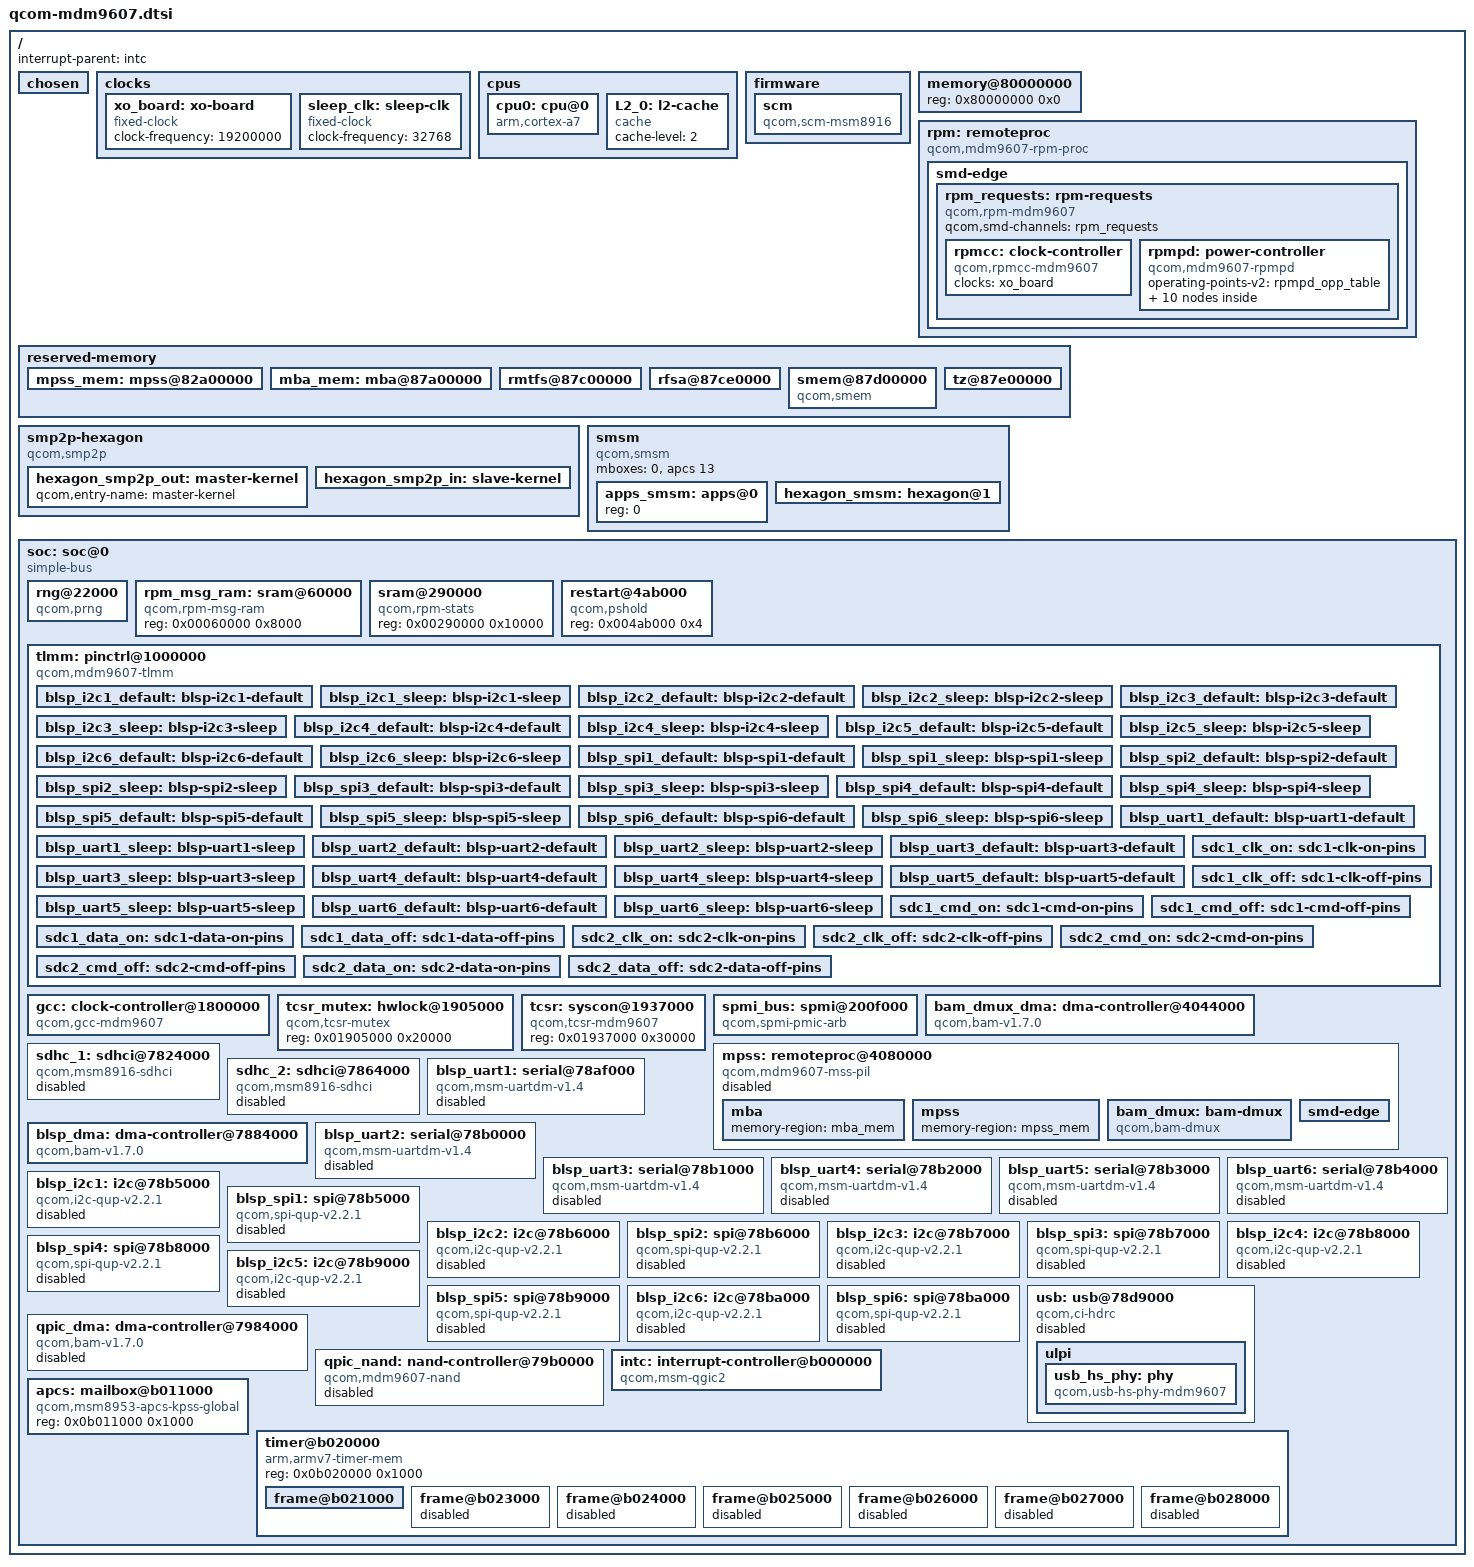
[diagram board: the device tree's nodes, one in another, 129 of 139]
// SPDX-License-Identifier: GPL-2.0-only
/*
 * Copyright (c) 2014-2019, The Linux Foundation. All rights reserved.
 */
/dts-v1/;

#include <dt-bindings/clock/qcom,gcc-mdm9607.h>
#include <dt-bindings/clock/qcom,rpmcc.h>
#include <dt-bindings/gpio/gpio.h>
#include <dt-bindings/interrupt-controller/arm-gic.h>
#include <dt-bindings/power/qcom-rpmpd.h>

/ {
	#address-cells = <1>;
	#size-cells = <1>;
	interrupt-parent = <&intc>;

	chosen { };

	clocks {
		xo_board: xo-board {
			compatible = "fixed-clock";
			#clock-cells = <0>;
			clock-frequency = <19200000>;
		};

		sleep_clk: sleep-clk {
			compatible = "fixed-clock";
			#clock-cells = <0>;
			clock-frequency = <32768>;
		};
	};

	cpus {
		#address-cells = <1>;
		#size-cells = <0>;

		cpu0: cpu@0 {
			device_type = "cpu";
			compatible = "arm,cortex-a7";
			reg = <0x0>;
			next-level-cache = <&L2_0>;
			#cooling-cells = <2>;
		};

		L2_0: l2-cache {
			compatible = "cache";
			cache-level = <2>;
		};
	};

	firmware {
		scm: scm {
			compatible = "qcom,scm-msm8916", "qcom,scm";
			clocks = <&gcc GCC_CRYPTO_CLK>,
				 <&gcc GCC_CRYPTO_AXI_CLK>,
				 <&gcc GCC_CRYPTO_AHB_CLK>;
			clock-names = "core", "bus", "iface";
			qcom,dload-mode = <&tcsr 0x6100>;
		};
	};

	memory@80000000 {
		device_type = "memory";
		/* We expect the bootloader to fill in the reg */
		reg = <0x80000000 0x0>;
	};

	rpm: remoteproc {
		compatible = "qcom,mdm9607-rpm-proc", "qcom,rpm-proc";

		smd-edge {
			interrupts = <GIC_SPI 168 IRQ_TYPE_EDGE_RISING>;
			mboxes = <&apcs 0>;
			qcom,smd-edge = <15>;

			rpm_requests: rpm-requests {
				compatible = "qcom,rpm-mdm9607", "qcom,smd-rpm";
				qcom,smd-channels = "rpm_requests";

				rpmcc: clock-controller {
					compatible = "qcom,rpmcc-mdm9607", "qcom,rpmcc";
					#clock-cells = <1>;
					clocks = <&xo_board>;
					clock-names = "xo";
				};

				rpmpd: power-controller {
					compatible = "qcom,mdm9607-rpmpd";
					#power-domain-cells = <1>;
					operating-points-v2 = <&rpmpd_opp_table>;

					rpmpd_opp_table: opp-table {
						compatible = "operating-points-v2";

						rpmpd_opp_ret: opp1 {
							opp-level = <RPM_SMD_LEVEL_RETENTION>;
						};
						rpmpd_opp_ret_plus: opp2 {
							opp-level = <RPM_SMD_LEVEL_RETENTION_PLUS>;
						};
						rpmpd_opp_min_svs: opp3 {
							opp-level = <RPM_SMD_LEVEL_MIN_SVS>;
						};
						rpmpd_opp_low_svs: opp4 {
							opp-level = <RPM_SMD_LEVEL_LOW_SVS>;
						};
						rpmpd_opp_svs: opp5 {
							opp-level = <RPM_SMD_LEVEL_SVS>;
						};
						rpmpd_opp_svs_plus: opp6 {
							opp-level = <RPM_SMD_LEVEL_SVS_PLUS>;
						};
						rpmpd_opp_nom: opp7 {
							opp-level = <RPM_SMD_LEVEL_NOM>;
						};
						rpmpd_opp_nom_plus: opp8 {
							opp-level = <RPM_SMD_LEVEL_NOM_PLUS>;
						};
						rpmpd_opp_turbo: opp9 {
							opp-level = <RPM_SMD_LEVEL_TURBO>;
						};
					};
				};
			};
		};
	};

	reserved-memory {
		#address-cells = <1>;
		#size-cells = <1>;
		ranges;

		mpss_mem: mpss@82a00000 {
			reg = <0x82a00000 0x5000000>;
			no-map;
		};
		mba_mem: mba@87a00000 {
			reg = <0x87a00000 0x100000>;
			no-map;
		};

		rmtfs@87c00000 {
			reg = <0x87c00000 0xe0000>;
			no-map;
		};
		rfsa@87ce0000 {
			reg = <0x87ce0000 0x20000>;
			no-map;
		};
		smem@87d00000 {
			compatible = "qcom,smem";
			reg = <0x87d00000 0x100000>;
			no-map;

			hwlocks = <&tcsr_mutex 3>;
			qcom,rpm-msg-ram = <&rpm_msg_ram>;
		};
		tz@87e00000 {
			reg = <0x87e00000 0x200000>;
			no-map;
		};
	};

	smp2p-hexagon {
		compatible = "qcom,smp2p";
		qcom,smem = <435>, <428>;

		interrupts = <GIC_SPI 27 IRQ_TYPE_EDGE_RISING>;

		mboxes = <&apcs 14>;

		qcom,local-pid = <0>;
		qcom,remote-pid = <1>;

		hexagon_smp2p_out: master-kernel {
			qcom,entry-name = "master-kernel";

			#qcom,smem-state-cells = <1>;
		};

		hexagon_smp2p_in: slave-kernel {
			qcom,entry-name = "slave-kernel";

			interrupt-controller;
			#interrupt-cells = <2>;
		};
	};

	smsm {
		compatible = "qcom,smsm";

		#address-cells = <1>;
		#size-cells = <0>;

		mboxes = <0>, <&apcs 13>;

		apps_smsm: apps@0 {
			reg = <0>;

			#qcom,smem-state-cells = <1>;
		};

		hexagon_smsm: hexagon@1 {
			reg = <1>;
			interrupts = <GIC_SPI 26 IRQ_TYPE_EDGE_RISING>;

			interrupt-controller;
			#interrupt-cells = <2>;
		};
	};

	soc: soc@0 {
		compatible = "simple-bus";
		#address-cells = <1>;
		#size-cells = <1>;
		ranges;

		rng@22000 {
			compatible = "qcom,prng";
			reg = <0x00022000 0x200>;
			clocks = <&gcc GCC_PRNG_AHB_CLK>;
			clock-names = "core";
		};

		rpm_msg_ram: sram@60000 {
			compatible = "qcom,rpm-msg-ram";
			reg = <0x00060000 0x8000>;
		};

		sram@290000 {
			compatible = "qcom,rpm-stats";
			reg = <0x00290000 0x10000>;
		};

		restart@4ab000 {
			compatible = "qcom,pshold";
			reg = <0x004ab000 0x4>;
		};

		tlmm: pinctrl@1000000 {
			compatible = "qcom,mdm9607-tlmm";
			reg = <0x01000000 0x300000>;
			interrupts = <GIC_SPI 208 IRQ_TYPE_LEVEL_HIGH>;
			gpio-controller;
			#gpio-cells = <2>;
			gpio-ranges = <&tlmm 0 0 117>;
			interrupt-controller;
			#interrupt-cells = <2>;

			blsp_i2c1_default: blsp-i2c1-default {
				pins = "gpio14", "gpio15";
				function = "blsp_i2c1";

				drive-strength = <2>;
				bias-disable;
			};

			blsp_i2c1_sleep: blsp-i2c1-sleep {
				pins = "gpio14", "gpio15";
				function = "gpio";

				drive-strength = <2>;
				bias-disable;
			};

			blsp_i2c2_default: blsp-i2c2-default {
				pins = "gpio6", "gpio7";
				function = "blsp_i2c2";

				drive-strength = <2>;
				bias-disable;
			};

			blsp_i2c2_sleep: blsp-i2c2-sleep {
				pins = "gpio6", "gpio7";
				function = "gpio";

				drive-strength = <2>;
				bias-disable;
			};

			blsp_i2c3_default: blsp-i2c3-default {
				pins = "gpio2", "gpio3";
				function = "blsp_i2c3";

				drive-strength = <2>;
				bias-disable;
			};

			blsp_i2c3_sleep: blsp-i2c3-sleep {
				pins = "gpio2", "gpio3";
				function = "gpio";

				drive-strength = <2>;
				bias-disable;
			};

			blsp_i2c4_default: blsp-i2c4-default {
				pins = "gpio18", "gpio19";
				function = "blsp_i2c4";

				drive-strength = <2>;
				bias-disable;
			};

			blsp_i2c4_sleep: blsp-i2c4-sleep {
				pins = "gpio18", "gpio19";
				function = "gpio";

				drive-strength = <2>;
				bias-disable;
			};

			blsp_i2c5_default: blsp-i2c5-default {
				pins = "gpio10", "gpio11";
				function = "blsp_i2c5";

				drive-strength = <2>;
				bias-disable;
			};

			blsp_i2c5_sleep: blsp-i2c5-sleep {
				pins = "gpio10", "gpio11";
				function = "gpio";

				drive-strength = <2>;
				bias-disable;
			};

			blsp_i2c6_default: blsp-i2c6-default {
				pins = "gpio22", "gpio23";
				function = "blsp_i2c6";

				drive-strength = <2>;
				bias-disable;
			};

			blsp_i2c6_sleep: blsp-i2c6-sleep {
				pins = "gpio22", "gpio23";
				function = "gpio";

				drive-strength = <2>;
				bias-disable;
			};

			blsp_spi1_default: blsp-spi1-default {
				pins = "gpio12", "gpio13", "gpio14", "gpio15";
				function = "blsp_spi1";

				drive-strength = <12>;
				bias-disable;
			};

			blsp_spi1_sleep: blsp-spi1-sleep {
				pins = "gpio12", "gpio13", "gpio14", "gpio15";
				function = "gpio";

				drive-strength = <2>;
				bias-pull-down;
			};

			blsp_spi2_default: blsp-spi2-default {
				pins = "gpio4", "gpio5", "gpio6", "gpio7";
				function = "blsp_spi2";

				drive-strength = <12>;
				bias-disable;
			};

			blsp_spi2_sleep: blsp-spi2-sleep {
				pins = "gpio4", "gpio5", "gpio6", "gpio7";
				function = "gpio";

				drive-strength = <2>;
				bias-pull-down;
			};

			blsp_spi3_default: blsp-spi3-default {
				pins = "gpio0", "gpio1", "gpio2", "gpio3";
				function = "blsp_spi3";

				drive-strength = <12>;
				bias-disable;
			};

			blsp_spi3_sleep: blsp-spi3-sleep {
				pins = "gpio0", "gpio1", "gpio2", "gpio3";
				function = "gpio";

				drive-strength = <2>;
				bias-pull-down;
			};

			blsp_spi4_default: blsp-spi4-default {
				pins = "gpio16", "gpio17", "gpio18", "gpio19";
				function = "blsp_spi4";

				drive-strength = <12>;
				bias-disable;
			};

			blsp_spi4_sleep: blsp-spi4-sleep {
				pins = "gpio16", "gpio17", "gpio18", "gpio19";
				function = "gpio";

				drive-strength = <2>;
				bias-pull-down;
			};

			blsp_spi5_default: blsp-spi5-default {
				pins = "gpio8", "gpio9", "gpio10", "gpio11";
				function = "blsp_spi5";

				drive-strength = <12>;
				bias-disable;
			};

			blsp_spi5_sleep: blsp-spi5-sleep {
				pins = "gpio8", "gpio9", "gpio10", "gpio11";
				function = "gpio";

				drive-strength = <2>;
				bias-pull-down;
			};

			blsp_spi6_default: blsp-spi6-default {
				pins = "gpio20", "gpio21", "gpio22", "gpio23";
				function = "blsp_spi6";

				drive-strength = <12>;
				bias-disable;
			};

			blsp_spi6_sleep: blsp-spi6-sleep {
				pins = "gpio20", "gpio21", "gpio22", "gpio23";
				function = "gpio";

				drive-strength = <2>;
				bias-pull-down;
			};

			blsp_uart1_default: blsp-uart1-default {
				pins = "gpio12", "gpio13", "gpio14", "gpio15";
				function = "blsp_uart1";

				drive-strength = <2>;
				bias-disable;
			};

			blsp_uart1_sleep: blsp-uart1-sleep {
				pins = "gpio12", "gpio13", "gpio14", "gpio15";
				function = "gpio";

				drive-strength = <2>;
				bias-pull-down;
			};

			blsp_uart2_default: blsp-uart2-default {
				pins = "gpio4", "gpio5", "gpio6", "gpio7";
				function = "blsp_uart2";

				drive-strength = <2>;
				bias-disable;
			};

			blsp_uart2_sleep: blsp-uart2-sleep {
				pins = "gpio4", "gpio5", "gpio6", "gpio7";
				function = "gpio";

				drive-strength = <2>;
				bias-pull-down;
			};

			blsp_uart3_default: blsp-uart3-default {
				pins = "gpio0", "gpio1", "gpio2", "gpio3";
				function = "blsp_uart3";

				drive-strength = <2>;
				bias-disable;
			};

			blsp_uart3_sleep: blsp-uart3-sleep {
				pins = "gpio0", "gpio1", "gpio2", "gpio3";
				function = "gpio";

				drive-strength = <2>;
				bias-pull-down;
			};

			blsp_uart4_default: blsp-uart4-default {
				pins = "gpio16", "gpio17", "gpio18", "gpio19";
				function = "blsp_uart4";

				drive-strength = <2>;
				bias-disable;
			};

			blsp_uart4_sleep: blsp-uart4-sleep {
				pins = "gpio16", "gpio17", "gpio18", "gpio19";
				function = "gpio";

				drive-strength = <2>;
				bias-pull-down;
			};

			blsp_uart5_default: blsp-uart5-default {
				pins = "gpio8", "gpio9";
				function = "blsp_uart5";

				drive-strength = <2>;
				bias-disable;
			};

			blsp_uart5_sleep: blsp-uart5-sleep {
				pins = "gpio8", "gpio9";
				function = "gpio";

				drive-strength = <2>;
				bias-pull-down;
			};

			blsp_uart6_default: blsp-uart6-default {
				pins = "gpio20", "gpio21", "gpio22", "gpio23";
				function = "blsp_uart6";

				drive-strength = <2>;
				bias-disable;
			};

			blsp_uart6_sleep: blsp-uart6-sleep {
				pins = "gpio20", "gpio21", "gpio22", "gpio23";
				function = "gpio";

				drive-strength = <2>;
				bias-pull-down;
			};

			sdc1_clk_on: sdc1-clk-on-pins {
				pins = "sdc1_clk";
				bias-disable;
				drive-strength = <16>;
			};

			sdc1_clk_off: sdc1-clk-off-pins {
				pins = "sdc1_clk";
				bias-disable;
				drive-strength = <2>;
			};

			sdc1_cmd_on: sdc1-cmd-on-pins {
				pins = "sdc1_cmd";
				bias-disable;
				drive-strength = <10>;
			};

			sdc1_cmd_off: sdc1-cmd-off-pins {
				pins = "sdc1_cmd";
				bias-disable;
				drive-strength = <2>;
			};

			sdc1_data_on: sdc1-data-on-pins {
				pins = "sdc1_data";
				bias-pull-up;
				drive-strength = <10>;
			};

			sdc1_data_off: sdc1-data-off-pins {
				pins = "sdc1_data";
				bias-pull-up;
				drive-strength = <2>;
			};

			sdc2_clk_on: sdc2-clk-on-pins {
				pins = "sdc2_clk";
				drive-strength = <16>;
				bias-disable;
			};

			sdc2_clk_off: sdc2-clk-off-pins {
				pins = "sdc2_clk";
				bias-disable;
				drive-strength = <2>;
			};

			sdc2_cmd_on: sdc2-cmd-on-pins {
				pins = "sdc2_cmd";
				bias-pull-up;
				drive-strength = <10>;
			};

			sdc2_cmd_off: sdc2-cmd-off-pins {
				pins = "sdc2_cmd";
				bias-pull-up;
				drive-strength = <2>;
			};

			sdc2_data_on: sdc2-data-on-pins {
				pins = "sdc2_data";
				bias-pull-up;
				drive-strength = <10>;
			};

			sdc2_data_off: sdc2-data-off-pins {
				pins = "sdc2_data";
				bias-pull-up;
				drive-strength = <2>;
			};
		};

		gcc: clock-controller@1800000 {
			compatible = "qcom,gcc-mdm9607";
			reg = <0x01800000 0x80000>;
			#clock-cells = <1>;
			#reset-cells = <1>;
			#power-domain-cells = <1>;
			clocks = <&xo_board>, <&sleep_clk>;
			clock-names = "xo", "sleep_clk";
		};

		tcsr_mutex: hwlock@1905000 {
			compatible = "qcom,tcsr-mutex";
			reg = <0x01905000 0x20000>;
			#hwlock-cells = <1>;
		};

		tcsr: syscon@1937000 {
			compatible = "qcom,tcsr-mdm9607", "syscon";
			reg = <0x01937000 0x30000>;
		};

		spmi_bus: spmi@200f000 {
			compatible = "qcom,spmi-pmic-arb";
			reg = <0x0200f000 0x001000>,
			      <0x02400000 0x400000>,
			      <0x02c00000 0x400000>,
			      <0x03800000 0x200000>,
			      <0x0200a000 0x002100>;
			reg-names = "core", "chnls", "obsrvr", "intr", "cnfg";
			interrupt-names = "periph_irq";
			interrupts = <GIC_SPI 190 IRQ_TYPE_LEVEL_HIGH>;
			qcom,ee = <0>;
			qcom,channel = <0>;
			#address-cells = <2>;
			#size-cells = <0>;
			interrupt-controller;
			#interrupt-cells = <4>;
		};

		bam_dmux_dma: dma-controller@4044000 {
			compatible = "qcom,bam-v1.7.0";
			reg = <0x04044000 0x19000>;
			interrupts = <GIC_SPI 29 IRQ_TYPE_LEVEL_HIGH>;
			#dma-cells = <1>;
			qcom,ee = <0>;

			num-channels = <6>;
			qcom,num-ees = <1>;
			qcom,powered-remotely;
		};

		mpss: remoteproc@4080000 {
			compatible = "qcom,mdm9607-mss-pil";
			reg = <0x04080000 0x100>,
			      <0x04020000 0x040>;
			reg-names = "qdsp6", "rmb";

			interrupts-extended = <&intc GIC_SPI 24 IRQ_TYPE_EDGE_RISING>,
					      <&hexagon_smp2p_in 0 IRQ_TYPE_EDGE_RISING>,
					      <&hexagon_smp2p_in 1 IRQ_TYPE_EDGE_RISING>,
					      <&hexagon_smp2p_in 2 IRQ_TYPE_EDGE_RISING>,
					      <&hexagon_smp2p_in 3 IRQ_TYPE_EDGE_RISING>;
			interrupt-names = "wdog", "fatal", "ready",
					  "handover", "stop-ack";

			power-domains = <&rpmpd MDM9607_VDDCX>,
					<&rpmpd MDM9607_VDDMX>;
			power-domain-names = "cx", "mx";

			clocks = <&gcc GCC_MSS_CFG_AHB_CLK>,
				 <&gcc GCC_MSS_Q6_BIMC_AXI_CLK>,
				 <&gcc GCC_BOOT_ROM_AHB_CLK>,
				 <&xo_board>;
			clock-names = "iface", "bus", "mem", "xo";

			qcom,smem-states = <&hexagon_smp2p_out 0>;
			qcom,smem-state-names = "stop";

			resets = <&gcc GCC_MSS_RESTART>;
			reset-names = "mss_restart";

			qcom,halt-regs = <&tcsr 0x18000 0x19000 0x1a000>;

			status = "disabled";

			mba {
				memory-region = <&mba_mem>;
			};

			mpss {
				memory-region = <&mpss_mem>;
			};

			bam_dmux: bam-dmux {
				compatible = "qcom,bam-dmux";

				interrupt-parent = <&hexagon_smsm>;
				interrupts = <1 IRQ_TYPE_EDGE_BOTH>, <11 IRQ_TYPE_EDGE_BOTH>;
				interrupt-names = "pc", "pc-ack";

				qcom,smem-states = <&apps_smsm 1>, <&apps_smsm 11>;
				qcom,smem-state-names = "pc", "pc-ack";

				dmas = <&bam_dmux_dma 4>, <&bam_dmux_dma 5>;
				dma-names = "tx", "rx";
			};

			smd-edge {
				interrupts = <GIC_SPI 25 IRQ_TYPE_EDGE_RISING>;

				qcom,smd-edge = <0>;
				mboxes = <&apcs 12>;
				qcom,remote-pid = <1>;

				label = "hexagon";
			};
		};

		sdhc_1: sdhci@7824000 {
			compatible = "qcom,msm8916-sdhci", "qcom,sdhci-msm-v4";
			reg = <0x07824900 0x11c>, <0x07824000 0x800>;
			reg-names = "hc_mem", "core_mem";

			interrupts = <GIC_SPI 123 IRQ_TYPE_LEVEL_HIGH>,
				     <GIC_SPI 138 IRQ_TYPE_LEVEL_HIGH>;
			interrupt-names = "hc_irq", "pwr_irq";
			clocks = <&gcc GCC_SDCC1_APPS_CLK>,
				 <&gcc GCC_SDCC1_AHB_CLK>,
				 <&xo_board>;
			clock-names = "core", "iface", "xo";

			pinctrl-names = "default", "sleep";
			pinctrl-0 = <&sdc1_clk_on &sdc1_cmd_on &sdc1_data_on>;
			pinctrl-1 = <&sdc1_clk_off &sdc1_cmd_off &sdc1_data_off>;

			bus-width = <4>;
			status = "disabled";
		};

		sdhc_2: sdhci@7864000 {
			compatible = "qcom,msm8916-sdhci", "qcom,sdhci-msm-v4";
			reg = <0x07864900 0x11c>, <0x07864000 0x800>;
			reg-names = "hc_mem", "core_mem";

			interrupts = <GIC_SPI 125 IRQ_TYPE_LEVEL_HIGH>,
				     <GIC_SPI 221 IRQ_TYPE_LEVEL_HIGH>;
			interrupt-names = "hc_irq", "pwr_irq";
			clocks = <&gcc GCC_SDCC2_APPS_CLK>,
				 <&gcc GCC_SDCC2_AHB_CLK>,
				 <&xo_board>;
			clock-names = "core", "iface", "xo";

			pinctrl-names = "default", "sleep";
			pinctrl-0 = <&sdc2_clk_on &sdc2_cmd_on &sdc2_data_on>;
			pinctrl-1 = <&sdc2_clk_off &sdc2_cmd_off &sdc2_data_off>;

			bus-width = <4>;
			status = "disabled";
		};

		blsp_dma: dma-controller@7884000 {
			compatible = "qcom,bam-v1.7.0";
			reg = <0x07884000 0x23000>;
			interrupts = <GIC_SPI 238 IRQ_TYPE_LEVEL_HIGH>;
			clocks = <&gcc GCC_BLSP1_AHB_CLK>;
			clock-names = "bam_clk";
			#dma-cells = <1>;
			qcom,ee = <0>;
			qcom,controlled-remotely;
		};

		blsp_uart1: serial@78af000 {
			compatible = "qcom,msm-uartdm-v1.4", "qcom,msm-uartdm";
			reg = <0x078af000 0x200>;
			interrupts = <GIC_SPI 107 IRQ_TYPE_LEVEL_HIGH>;
			clocks = <&gcc GCC_BLSP1_UART1_APPS_CLK>,
				 <&gcc GCC_BLSP1_AHB_CLK>;
			clock-names = "core", "iface";
			dmas = <&blsp_dma 0>, <&blsp_dma 1>;
			dma-names = "tx", "rx";
			pinctrl-names = "default", "sleep";
			pinctrl-0 = <&blsp_uart1_default>;
			pinctrl-1 = <&blsp_uart1_sleep>;
			status = "disabled";
		};

		blsp_uart2: serial@78b0000 {
			compatible = "qcom,msm-uartdm-v1.4", "qcom,msm-uartdm";
			reg = <0x078b0000 0x200>;
			interrupts = <GIC_SPI 108 IRQ_TYPE_LEVEL_HIGH>;
			clocks = <&gcc GCC_BLSP1_UART2_APPS_CLK>,
				 <&gcc GCC_BLSP1_AHB_CLK>;
			clock-names = "core", "iface";
			dmas = <&blsp_dma 2>, <&blsp_dma 3>;
			dma-names = "tx", "rx";
			pinctrl-names = "default", "sleep";
			pinctrl-0 = <&blsp_uart2_default>;
			pinctrl-1 = <&blsp_uart2_sleep>;
			status = "disabled";
		};

		blsp_uart3: serial@78b1000 {
			compatible = "qcom,msm-uartdm-v1.4", "qcom,msm-uartdm";
			reg = <0x078b1000 0x200>;
			interrupts = <GIC_SPI 119 IRQ_TYPE_LEVEL_HIGH>;
			clocks = <&gcc GCC_BLSP1_UART3_APPS_CLK>,
				 <&gcc GCC_BLSP1_AHB_CLK>;
			clock-names = "core", "iface";
			dmas = <&blsp_dma 4>, <&blsp_dma 5>;
			dma-names = "tx", "rx";
			pinctrl-names = "default", "sleep";
			pinctrl-0 = <&blsp_uart3_default>;
			pinctrl-1 = <&blsp_uart3_sleep>;
			status = "disabled";
		};

		blsp_uart4: serial@78b2000 {
			compatible = "qcom,msm-uartdm-v1.4", "qcom,msm-uartdm";
			reg = <0x078b2000 0x200>;
			interrupts = <GIC_SPI 120 IRQ_TYPE_LEVEL_HIGH>;
			clocks = <&gcc GCC_BLSP1_UART4_APPS_CLK>,
				 <&gcc GCC_BLSP1_AHB_CLK>;
			clock-names = "core", "iface";
			dmas = <&blsp_dma 6>, <&blsp_dma 7>;
			dma-names = "tx", "rx";
			pinctrl-names = "default", "sleep";
			pinctrl-0 = <&blsp_uart4_default>;
			pinctrl-1 = <&blsp_uart4_sleep>;
			status = "disabled";
		};

		blsp_uart5: serial@78b3000 {
			compatible = "qcom,msm-uartdm-v1.4", "qcom,msm-uartdm";
			reg = <0x078b3000 0x200>;
			interrupts = <GIC_SPI 121 IRQ_TYPE_LEVEL_HIGH>;
			clocks = <&gcc GCC_BLSP1_UART5_APPS_CLK>,
				 <&gcc GCC_BLSP1_AHB_CLK>;
			clock-names = "core", "iface";
			dmas = <&blsp_dma 8>, <&blsp_dma 9>;
			dma-names = "tx", "rx";
			pinctrl-names = "default", "sleep";
			pinctrl-0 = <&blsp_uart5_default>;
			pinctrl-1 = <&blsp_uart5_sleep>;
			status = "disabled";
		};

		blsp_uart6: serial@78b4000 {
			compatible = "qcom,msm-uartdm-v1.4", "qcom,msm-uartdm";
			reg = <0x078b4000 0x200>;
			interrupts = <GIC_SPI 122 IRQ_TYPE_LEVEL_HIGH>;
			clocks = <&gcc GCC_BLSP1_UART6_APPS_CLK>,
				 <&gcc GCC_BLSP1_AHB_CLK>;
			clock-names = "core", "iface";
			dmas = <&blsp_dma 10>, <&blsp_dma 11>;
			dma-names = "tx", "rx";
			pinctrl-names = "default", "sleep";
			pinctrl-0 = <&blsp_uart6_default>;
			pinctrl-1 = <&blsp_uart6_sleep>;
			status = "disabled";
		};

		blsp_i2c1: i2c@78b5000 {
			compatible = "qcom,i2c-qup-v2.2.1";
			reg = <0x078b5000 0x500>;
			interrupts = <GIC_SPI 95 IRQ_TYPE_LEVEL_HIGH>;
			clocks = <&gcc GCC_BLSP1_QUP1_I2C_APPS_CLK>,
				 <&gcc GCC_BLSP1_AHB_CLK>;
			clock-names = "core", "iface";
			dmas = <&blsp_dma 12>, <&blsp_dma 13>;
			dma-names = "tx", "rx";
			pinctrl-names = "default", "sleep";
			pinctrl-0 = <&blsp_i2c1_default>;
			pinctrl-1 = <&blsp_i2c1_sleep>;
			#address-cells = <1>;
			#size-cells = <0>;
			status = "disabled";
		};

		blsp_spi1: spi@78b5000 {
			compatible = "qcom,spi-qup-v2.2.1";
			reg = <0x078b5000 0x500>;
			interrupts = <GIC_SPI 95 IRQ_TYPE_LEVEL_HIGH>;
			clocks = <&gcc GCC_BLSP1_QUP1_SPI_APPS_CLK>,
				 <&gcc GCC_BLSP1_AHB_CLK>;
			clock-names = "core", "iface";
			dmas = <&blsp_dma 12>, <&blsp_dma 13>;
			dma-names = "tx", "rx";
			pinctrl-names = "default", "sleep";
			pinctrl-0 = <&blsp_spi1_default>;
			pinctrl-1 = <&blsp_spi1_sleep>;
			#address-cells = <1>;
			#size-cells = <0>;
			status = "disabled";
		};

		blsp_i2c2: i2c@78b6000 {
			compatible = "qcom,i2c-qup-v2.2.1";
			reg = <0x078b6000 0x500>;
			interrupts = <GIC_SPI 96 IRQ_TYPE_LEVEL_HIGH>;
			clocks = <&gcc GCC_BLSP1_QUP2_I2C_APPS_CLK>,
				 <&gcc GCC_BLSP1_AHB_CLK>;
			clock-names = "core", "iface";
			dmas = <&blsp_dma 14>, <&blsp_dma 15>;
			dma-names = "tx", "rx";
			pinctrl-names = "default", "sleep";
			pinctrl-0 = <&blsp_i2c2_default>;
			pinctrl-1 = <&blsp_i2c2_sleep>;
			#address-cells = <1>;
			#size-cells = <0>;
			status = "disabled";
		};

		blsp_spi2: spi@78b6000 {
			compatible = "qcom,spi-qup-v2.2.1";
			reg = <0x078b6000 0x500>;
			interrupts = <GIC_SPI 96 IRQ_TYPE_LEVEL_HIGH>;
			clocks = <&gcc GCC_BLSP1_QUP2_SPI_APPS_CLK>,
				 <&gcc GCC_BLSP1_AHB_CLK>;
			clock-names = "core", "iface";
			dmas = <&blsp_dma 14>, <&blsp_dma 15>;
			dma-names = "tx", "rx";
			pinctrl-names = "default", "sleep";
			pinctrl-0 = <&blsp_spi2_default>;
			pinctrl-1 = <&blsp_spi2_sleep>;
			#address-cells = <1>;
			#size-cells = <0>;
			status = "disabled";
		};

		blsp_i2c3: i2c@78b7000 {
			compatible = "qcom,i2c-qup-v2.2.1";
			reg = <0x078b7000 0x500>;
			interrupts = <GIC_SPI 97 IRQ_TYPE_LEVEL_HIGH>;
			clocks = <&gcc GCC_BLSP1_QUP3_I2C_APPS_CLK>,
				 <&gcc GCC_BLSP1_AHB_CLK>;
			clock-names = "core", "iface";
			dmas = <&blsp_dma 16>, <&blsp_dma 17>;
			dma-names = "tx", "rx";
			pinctrl-names = "default", "sleep";
			pinctrl-0 = <&blsp_i2c3_default>;
			pinctrl-1 = <&blsp_i2c3_sleep>;
			#address-cells = <1>;
			#size-cells = <0>;
			status = "disabled";
		};

		blsp_spi3: spi@78b7000 {
			compatible = "qcom,spi-qup-v2.2.1";
			reg = <0x078b7000 0x500>;
			interrupts = <GIC_SPI 97 IRQ_TYPE_LEVEL_HIGH>;
			clocks = <&gcc GCC_BLSP1_QUP3_SPI_APPS_CLK>,
				 <&gcc GCC_BLSP1_AHB_CLK>;
			clock-names = "core", "iface";
			dmas = <&blsp_dma 16>, <&blsp_dma 17>;
			dma-names = "tx", "rx";
			pinctrl-names = "default", "sleep";
			pinctrl-0 = <&blsp_spi3_default>;
			pinctrl-1 = <&blsp_spi3_sleep>;
			#address-cells = <1>;
			#size-cells = <0>;
			status = "disabled";
		};

		blsp_i2c4: i2c@78b8000 {
			compatible = "qcom,i2c-qup-v2.2.1";
			reg = <0x078b8000 0x500>;
			interrupts = <GIC_SPI 98 IRQ_TYPE_LEVEL_HIGH>;
			clocks = <&gcc GCC_BLSP1_QUP4_I2C_APPS_CLK>,
				 <&gcc GCC_BLSP1_AHB_CLK>;
			clock-names = "core", "iface";
			dmas = <&blsp_dma 18>, <&blsp_dma 19>;
			dma-names = "tx", "rx";
			pinctrl-names = "default", "sleep";
			pinctrl-0 = <&blsp_i2c4_default>;
			pinctrl-1 = <&blsp_i2c4_sleep>;
			#address-cells = <1>;
			#size-cells = <0>;
			status = "disabled";
		};

		blsp_spi4: spi@78b8000 {
			compatible = "qcom,spi-qup-v2.2.1";
			reg = <0x078b8000 0x500>;
			interrupts = <GIC_SPI 98 IRQ_TYPE_LEVEL_HIGH>;
			clocks = <&gcc GCC_BLSP1_QUP4_SPI_APPS_CLK>,
				 <&gcc GCC_BLSP1_AHB_CLK>;
			clock-names = "core", "iface";
			dmas = <&blsp_dma 18>, <&blsp_dma 19>;
			dma-names = "tx", "rx";
			pinctrl-names = "default", "sleep";
			pinctrl-0 = <&blsp_spi4_default>;
			pinctrl-1 = <&blsp_spi4_sleep>;
			#address-cells = <1>;
			#size-cells = <0>;
			status = "disabled";
		};

		blsp_i2c5: i2c@78b9000 {
			compatible = "qcom,i2c-qup-v2.2.1";
			reg = <0x078b9000 0x500>;
			interrupts = <GIC_SPI 99 IRQ_TYPE_LEVEL_HIGH>;
			clocks = <&gcc GCC_BLSP1_QUP5_I2C_APPS_CLK>,
				 <&gcc GCC_BLSP1_AHB_CLK>;
			clock-names = "core", "iface";
			dmas = <&blsp_dma 20>, <&blsp_dma 21>;
			dma-names = "tx", "rx";
			pinctrl-names = "default", "sleep";
			pinctrl-0 = <&blsp_i2c5_default>;
			pinctrl-1 = <&blsp_i2c5_sleep>;
			#address-cells = <1>;
			#size-cells = <0>;
			status = "disabled";
		};

		blsp_spi5: spi@78b9000 {
			compatible = "qcom,spi-qup-v2.2.1";
			reg = <0x078b9000 0x500>;
			interrupts = <GIC_SPI 99 IRQ_TYPE_LEVEL_HIGH>;
			clocks = <&gcc GCC_BLSP1_QUP5_SPI_APPS_CLK>,
				 <&gcc GCC_BLSP1_AHB_CLK>;
			clock-names = "core", "iface";
			dmas = <&blsp_dma 20>, <&blsp_dma 21>;
			dma-names = "tx", "rx";
			pinctrl-names = "default", "sleep";
			pinctrl-0 = <&blsp_spi5_default>;
			pinctrl-1 = <&blsp_spi5_sleep>;
			#address-cells = <1>;
			#size-cells = <0>;
			status = "disabled";
		};

		blsp_i2c6: i2c@78ba000 {
			compatible = "qcom,i2c-qup-v2.2.1";
			reg = <0x078ba000 0x500>;
			interrupts = <GIC_SPI 100 IRQ_TYPE_LEVEL_HIGH>;
			clocks = <&gcc GCC_BLSP1_QUP6_I2C_APPS_CLK>,
				 <&gcc GCC_BLSP1_AHB_CLK>;
			clock-names = "core", "iface";
			dmas = <&blsp_dma 22>, <&blsp_dma 23>;
			dma-names = "tx", "rx";
			pinctrl-names = "default", "sleep";
			pinctrl-0 = <&blsp_i2c6_default>;
			pinctrl-1 = <&blsp_i2c6_sleep>;
			#address-cells = <1>;
			#size-cells = <0>;
			status = "disabled";
		};

		blsp_spi6: spi@78ba000 {
			compatible = "qcom,spi-qup-v2.2.1";
			reg = <0x078ba000 0x500>;
			interrupts = <GIC_SPI 100 IRQ_TYPE_LEVEL_HIGH>;
			clocks = <&gcc GCC_BLSP1_QUP6_SPI_APPS_CLK>,
				 <&gcc GCC_BLSP1_AHB_CLK>;
			clock-names = "core", "iface";
			dmas = <&blsp_dma 22>, <&blsp_dma 23>;
			dma-names = "tx", "rx";
			pinctrl-names = "default", "sleep";
			pinctrl-0 = <&blsp_spi6_default>;
			pinctrl-1 = <&blsp_spi6_sleep>;
			#address-cells = <1>;
			#size-cells = <0>;
			status = "disabled";
		};

		usb: usb@78d9000 {
			compatible = "qcom,ci-hdrc";
			reg = <0x078d9000 0x200>, <0x078d9200 0x200>;
			interrupts = <GIC_SPI 134 IRQ_TYPE_LEVEL_HIGH>,
				     <GIC_SPI 140 IRQ_TYPE_LEVEL_HIGH>;
			clocks = <&gcc GCC_USB_HS_AHB_CLK>,
				 <&gcc GCC_USB_HS_SYSTEM_CLK>;
			clock-names = "iface", "core";
			assigned-clocks = <&gcc GCC_USB_HS_SYSTEM_CLK>;
			assigned-clock-rates = <133330000>;
			resets = <&gcc USB_HS_BCR>;
			reset-names = "core";
			phy_type = "ulpi";
			dr_mode = "otg";
			hnp-disable;
			srp-disable;
			adp-disable;
			ahb-burst-config = <0>;
			phy-names = "usb-phy";
			phys = <&usb_hs_phy>;
			status = "disabled";
			#reset-cells = <1>;

			ulpi {
				usb_hs_phy: phy {
					compatible = "qcom,usb-hs-phy-mdm9607",
						     "qcom,usb-hs-phy";
					#phy-cells = <0>;
					clocks = <&xo_board>, <&gcc GCC_USB2A_PHY_SLEEP_CLK>;
					clock-names = "ref", "sleep";
					resets = <&gcc QUSB2_PHY_BCR>,
						 <&gcc USB2_HS_PHY_ONLY_BCR>;
					reset-names = "phy", "por";
					qcom,init-seq = /bits/ 8 <0x0 0x44>,
								 <0x1 0x38>,
								 <0x2 0x24>,
								 <0x3 0x13>;
				};
			};
		};

		qpic_dma: dma-controller@7984000 {
			compatible = "qcom,bam-v1.7.0";
			reg = <0x07984000 0x1a000>;
			interrupts = <GIC_SPI 132 IRQ_TYPE_LEVEL_HIGH>;
			clocks = <&rpmcc RPM_SMD_QPIC_CLK>;
			clock-names = "bam_clk";
			#dma-cells = <1>;
			qcom,ee = <0>;
			qcom,controlled-remotely;
			status = "disabled";
		};

		qpic_nand: nand-controller@79b0000 {
			compatible = "qcom,mdm9607-nand";
			reg = <0x079b0000 0x1000>;
			clocks = <&rpmcc RPM_SMD_QPIC_CLK>,
				 <&rpmcc RPM_SMD_QPIC_CLK>;
			clock-names = "core", "aon";
			dmas = <&qpic_dma 0>, <&qpic_dma 1>, <&qpic_dma 2>;
			dma-names = "tx", "rx", "cmd";
			#address-cells = <1>;
			#size-cells = <0>;
			status = "disabled";
		};

		intc: interrupt-controller@b000000 {
			compatible = "qcom,msm-qgic2";
			reg = <0x0b000000 0x1000>,
			      <0x0b002000 0x1000>;
			interrupt-controller;
			#interrupt-cells = <3>;
		};

		apcs: mailbox@b011000 {
			compatible = "qcom,msm8953-apcs-kpss-global", "syscon";
			reg = <0x0b011000 0x1000>;
			#mbox-cells = <1>;
		};

		timer@b020000 {
			compatible = "arm,armv7-timer-mem";
			reg = <0x0b020000 0x1000>;
			#address-cells = <1>;
			#size-cells = <1>;
			ranges;

			frame@b021000 {
				reg = <0x0b021000 0x1000>, <0x0b022000 0x1000>;
				interrupts = <GIC_SPI 7 IRQ_TYPE_LEVEL_HIGH>,
					     <GIC_SPI 6 IRQ_TYPE_LEVEL_HIGH>;
				frame-number = <0>;
			};

			frame@b023000 {
				reg = <0x0b023000 0x1000>;
				interrupts = <GIC_SPI 9 IRQ_TYPE_LEVEL_HIGH>;
				frame-number = <1>;
				status = "disabled";
			};

			frame@b024000 {
				reg = <0x0b024000 0x1000>;
				interrupts = <GIC_SPI 10 IRQ_TYPE_LEVEL_HIGH>;
				frame-number = <2>;
				status = "disabled";
			};

			frame@b025000 {
				reg = <0x0b025000 0x1000>;
				interrupts = <GIC_SPI 11 IRQ_TYPE_LEVEL_HIGH>;
				frame-number = <3>;
				status = "disabled";
			};

			frame@b026000 {
				reg = <0x0b026000 0x1000>;
				interrupts = <GIC_SPI 12 IRQ_TYPE_LEVEL_HIGH>;
				frame-number = <4>;
				status = "disabled";
			};

			frame@b027000 {
				reg = <0x0b027000 0x1000>;
				interrupts = <GIC_SPI 13 IRQ_TYPE_LEVEL_HIGH>;
				frame-number = <5>;
				status = "disabled";
			};

			frame@b028000 {
				reg = <0x0b028000 0x1000>;
				interrupts = <GIC_SPI 14 IRQ_TYPE_LEVEL_HIGH>;
				frame-number = <6>;
				status = "disabled";
			};
		};
	};
};
